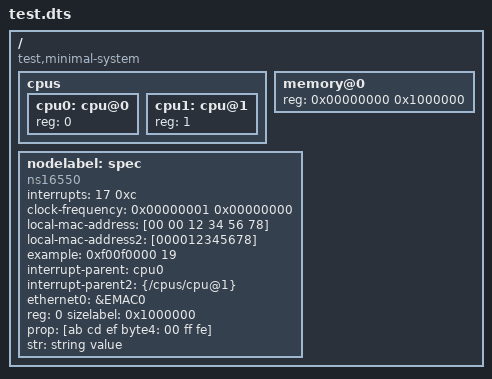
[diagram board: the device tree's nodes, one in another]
/dts-v1/;

/ {
    #address-cells = <1>;
    #size-cells = <1>;
    compatible = "test,minimal-system";

    cpus {
        #address-cells = <1>;
        #size-cells = <0>;

        cpu0: cpu@0 {
            device_type = "cpu";
            reg = <0>;
        };

        cpu1: cpu@1 {
            device_type = "cpu";
            reg = <1>;
        };
    };

    memory@0 {
        device_type = "memory";
        reg = <0x00000000 0x1000000>;
    };

    nodelabel: spec {
        interrupts = <17 0xc>;
        clock-frequency = <0x00000001 0x00000000>;

        local-mac-address = [00 00 12 34 56 78];
        local-mac-address2 = [000012345678];

        compatible = "ns16550", "ns8250";
        example = <0xf00f0000 19>, "a strange property format";

        interrupt-parent = < &cpu0 >;
        interrupt-parent2 = < &{/cpus/cpu@1} >;

        ethernet0 = &EMAC0;

        reg = reglabel: <0 sizelabel: 0x1000000>;
        prop = [ab cd ef byte4: 00 ff fe];
        str = start: "string value" end: ;
    };
};
